# wl_phy_tx_dfe_secure register map
Vendor: Texas Instruments
Peripheral module from a debugger description file (folder CC35X1).
Registers are 32-bit, access per field, reset values left out (the file's numbers can be read two ways) unless marked. A register's access mark holds for its fields unless they carry their own. Offsets are as the file gives them; lines under a group give offsets from that group; [hi:lo] are bit positions; {n}, {i} and the like mark numbered series; 'fields as' and 'values as' point back to an identical list; <NAME> marks a mode.

## wl_phy_tx_dfe_secure
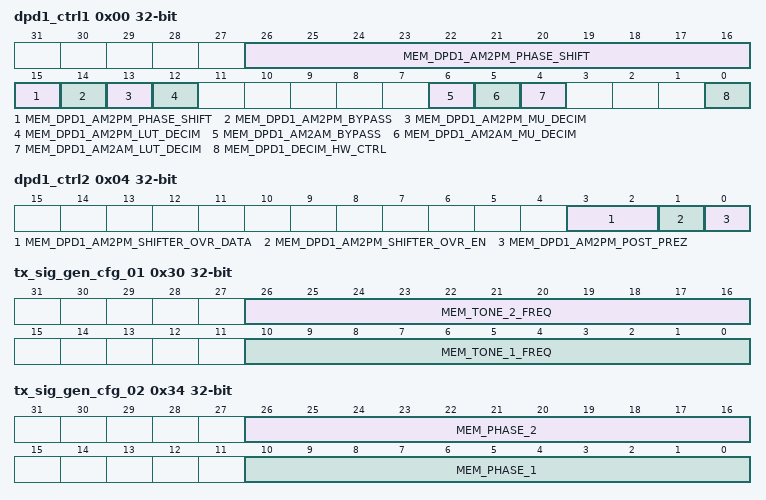
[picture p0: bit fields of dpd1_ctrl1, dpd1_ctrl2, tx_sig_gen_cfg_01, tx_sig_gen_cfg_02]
0x00 dpd1_ctrl1
  [26:15] MEM_DPD1_AM2PM_PHASE_SHIFT rw
  [14] MEM_DPD1_AM2PM_BYPASS rw
  [13] MEM_DPD1_AM2PM_MU_DECIM rw
  [12] MEM_DPD1_AM2PM_LUT_DECIM rw
  [6] MEM_DPD1_AM2AM_BYPASS rw
  [5] MEM_DPD1_AM2AM_MU_DECIM rw
  [4] MEM_DPD1_AM2AM_LUT_DECIM rw
  [0] MEM_DPD1_DECIM_HW_CTRL rw — 0 - DECM control bt MMR (at this Register) 1 - DECIM control from HW (at STF to LTF Boundry)
0x04 dpd1_ctrl2
  [3:2] MEM_DPD1_AM2PM_SHIFTER_OVR_DATA rw, [1] MEM_DPD1_AM2PM_SHIFTER_OVR_EN rw, [0] MEM_DPD1_AM2PM_POST_PREZ rw
0x10 tx_dfe_resamp_config
  [3:0] MEM_WR_PNT_RST_BIN rw — Resamp Write pointer init value
0x14 tx_dfe_resamp_stat ro — TX_DFE_RESAMP_CONFIG
  [4:0] FILLUP_80 — Resamp Write pointer init value
0x20 tx_dfe_iq_mm_config — TX_DFE_IF_CONFIG
  [0] MEM_TX_IQMM_CORR_BYPASS rw — 0- Interp by 4 (Also Clk div of 4) 1- interp by 3 (Also Clk div of 3)
0x30 tx_sig_gen_cfg_01
  [26:16] MEM_TONE_2_FREQ rw, [10:0] MEM_TONE_1_FREQ rw
0x34 tx_sig_gen_cfg_02
  [26:16] MEM_PHASE_2 rw, [10:0] MEM_PHASE_1 rw
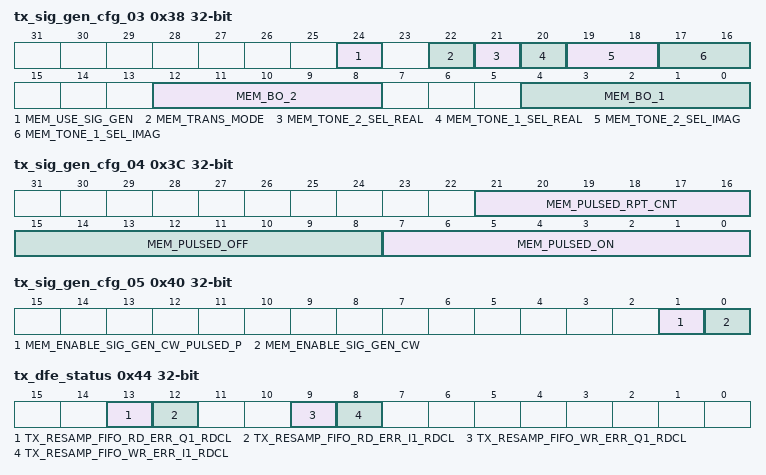
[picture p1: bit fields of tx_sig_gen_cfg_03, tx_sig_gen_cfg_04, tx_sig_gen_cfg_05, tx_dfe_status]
0x38 tx_sig_gen_cfg_03
  [24] MEM_USE_SIG_GEN rw — 1 - Select Sig Gen 0 - Normal mode
  [22] MEM_TRANS_MODE rw
  [21] MEM_TONE_2_SEL_REAL rw
  [20] MEM_TONE_1_SEL_REAL rw
  [19:18] MEM_TONE_2_SEL_IMAG rw
  [17:16] MEM_TONE_1_SEL_IMAG rw
  [12:8] MEM_BO_2 rw
  [4:0] MEM_BO_1 rw
0x3C tx_sig_gen_cfg_04
  [21:16] MEM_PULSED_RPT_CNT rw, [15:8] MEM_PULSED_OFF rw, [7:0] MEM_PULSED_ON rw
0x40 tx_sig_gen_cfg_05
  [1] MEM_ENABLE_SIG_GEN_CW_PULSED_P rw, [0] MEM_ENABLE_SIG_GEN_CW rw
0x44 tx_dfe_status
  [13] TX_RESAMP_FIFO_RD_ERR_Q1_RDCL wo, [12] TX_RESAMP_FIFO_RD_ERR_I1_RDCL wo, [9] TX_RESAMP_FIFO_WR_ERR_Q1_RDCL wo, [8] TX_RESAMP_FIFO_WR_ERR_I1_RDCL wo
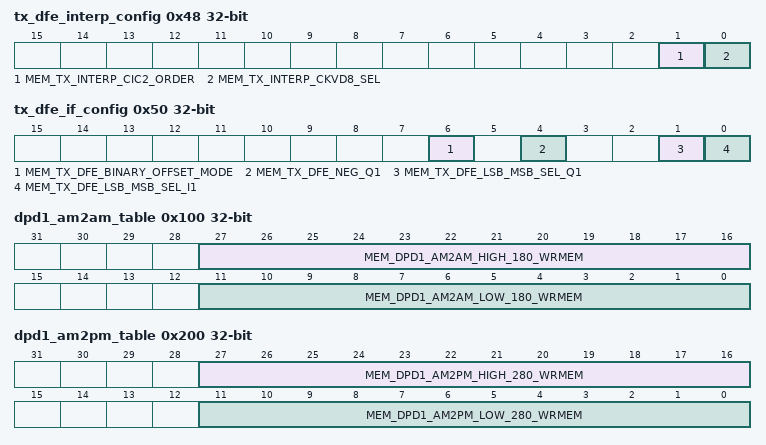
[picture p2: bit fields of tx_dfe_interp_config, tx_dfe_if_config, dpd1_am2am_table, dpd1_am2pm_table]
0x48 tx_dfe_interp_config — TX_DFE_IF_CONFIG
  [1] MEM_TX_INTERP_CIC2_ORDER rw — Function as Interp CIC-2-Order When set to '1' (Default Value). Otherwise, when set to '0' function as bypass mode (CIC-1-Order).
  [0] MEM_TX_INTERP_CKVD8_SEL rw — 0- Interp by 4 (Also Clk div of 4) 1- interp by 3 (Also Clk div of 3)
0x50 tx_dfe_if_config
  [6] MEM_TX_DFE_BINARY_OFFSET_MODE rw — 0 - Tx Data to Analog using TC format 1 - Tx Data to Analog using Binary Offset format
  [4] MEM_TX_DFE_NEG_Q1 rw
  [1] MEM_TX_DFE_LSB_MSB_SEL_Q1 rw
  [0] MEM_TX_DFE_LSB_MSB_SEL_I1 rw
0x54 tx_dfe_interp_sw_reset — TX_DFE_IF_CONFIG
  [0] MEM_TX_INTERP_SW_RESET_WRCL wo — Option to force Tx-Interp Reset by SW. Writing to this register - generate an a-synch reset pulse.
0x100 dpd1_am2am_table
  [27:16] MEM_DPD1_AM2AM_HIGH_180_WRMEM rw — DPD1_AM2AM_TABLE - Hign
  [11:0] MEM_DPD1_AM2AM_LOW_180_WRMEM rw — DPD1_AM2AM_TABLE - Low
0x200 dpd1_am2pm_table
  [27:16] MEM_DPD1_AM2PM_HIGH_280_WRMEM rw — DPD1_AM2PM_TABLE - High
  [11:0] MEM_DPD1_AM2PM_LOW_280_WRMEM rw — DPD1_AM2PM_TABLE - Low
